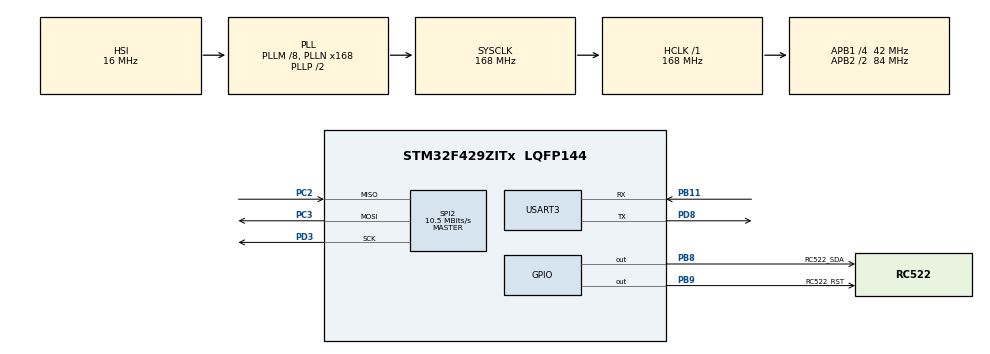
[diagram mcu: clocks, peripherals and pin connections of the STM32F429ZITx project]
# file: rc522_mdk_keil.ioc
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Mcu.Family=STM32F4
Mcu.Name=STM32F429ZITx
Mcu.Package=LQFP144
NVIC.PriorityGroup=NVIC_PRIORITYGROUP_4
NVIC.TIM1_UP_TIM10_IRQn=true\:15\:0\:false\:false\:true\:false\:true\:true
NVIC.TimeBase=TIM1_UP_TIM10_IRQn
NVIC.TimeBaseIP=TIM1
PA13.Mode=Serial_Wire
PA13.Signal=SYS_JTMS-SWDIO
PA14.Mode=Serial_Wire
PA14.Signal=SYS_JTCK-SWCLK
PB11.Mode=Asynchronous
PB11.Signal=USART3_RX
PB8.GPIO_Label=RC522_SDA
PB8.GPIO_Speed=GPIO_SPEED_FREQ_HIGH
PB8.Signal=GPIO_Output
PB9.GPIO_Label=RC522_RST
PB9.GPIO_Speed=GPIO_SPEED_FREQ_HIGH
PB9.Signal=GPIO_Output
PC2.Mode=Full_Duplex_Master
PC2.Signal=SPI2_MISO
PC3.Mode=Full_Duplex_Master
PC3.Signal=SPI2_MOSI
PD3.Mode=Full_Duplex_Master
PD3.Signal=SPI2_SCK
PD8.Mode=Asynchronous
PD8.Signal=USART3_TX
PH0/OSC_IN.Mode=HSE-External-Clock-Source
PH0/OSC_IN.Signal=RCC_OSC_IN
PH1/OSC_OUT.Mode=HSE-External-Clock-Source
PH1/OSC_OUT.Signal=RCC_OSC_OUT
ProjectManager.HeapSize=0x200
ProjectManager.StackSize=0x400
ProjectManager.TargetToolchain=MDK-ARM V5.32
RCC.48MHZClocksFreq_Value=48000000
RCC.AHBFreq_Value=168000000
RCC.APB1CLKDivider=RCC_HCLK_DIV4
RCC.APB1Freq_Value=42000000
RCC.APB1TimFreq_Value=84000000
RCC.APB2CLKDivider=RCC_HCLK_DIV2
RCC.APB2Freq_Value=84000000
RCC.APB2TimFreq_Value=168000000
RCC.CortexFreq_Value=168000000
RCC.HCLKFreq_Value=168000000
RCC.HSE_VALUE=8000000
RCC.HSI_VALUE=16000000
RCC.LSE_VALUE=32768
RCC.PLLM=8
RCC.PLLMUL=RCC_PLL_MUL9
RCC.PLLN=168
RCC.PLLQ=7
RCC.PRESCALERUSB=RCC_USBCLKSOURCE_PLL_DIV1_5
RCC.SYSCLKFreq_VALUE=168000000
RCC.SYSCLKSource=RCC_SYSCLKSOURCE_PLLCLK
RCC.SYSCLKSourceVirtual=RCC_SYSCLKSOURCE_PLLCLK
RCC.USBFreq_Value=48000000
RCC.VCOOutputFreq_Value=336000000
SPI2.BaudRatePrescaler=SPI_BAUDRATEPRESCALER_4
SPI2.CalculateBaudRate=10.5 MBits/s
SPI2.Direction=SPI_DIRECTION_2LINES
SPI2.Mode=SPI_MODE_MASTER
SPI2.VirtualType=VM_MASTER
USART3.VirtualMode=VM_ASYNC
VP_SYS_VS_tim1.Mode=TIM1
VP_TIM2_VS_ClockSourceINT.Mode=Internal
board=NUCLEO-F429ZI

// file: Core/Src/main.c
/* USER CODE BEGIN Header */
/**
  ******************************************************************************
  * @file           : main.c
  * @brief          : Main program body
  ******************************************************************************
  * @attention
  *
  * Copyright (c) 2023 STMicroelectronics.
  * All rights reserved.
  *
  * This software is licensed under terms that can be found in the LICENSE file
  * in the root directory of this software component.
  * If no LICENSE file comes with this software, it is provided AS-IS.
  *
  ******************************************************************************
  */
/* USER CODE END Header */
#include "main.h"
#include "spi.h"
#include "tim.h"
#include "usart.h"
#include "gpio.h"

/* USER CODE BEGIN Includes */
#include "rc522.h"
#include "stdio.h"
/* USER CODE END Includes */

void SystemClock_Config(void);

int main(void)
{

  /* MCU Configuration--------------------------------------------------------*/

  /* Reset of all peripherals, Initializes the Flash interface and the Systick. */
  HAL_Init();

  /* Configure the system clock */
  SystemClock_Config();

  /* Initialize all configured peripherals */
  MX_GPIO_Init();
  MX_SPI2_Init();
  MX_USART3_UART_Init();
  MX_TIM2_Init();
  /* USER CODE BEGIN 2 */
	printf("system start\r\n");
	RC522_Init();
	//printf("system start\n");
  /* USER CODE END 2 */

  /* Infinite loop */
  /* USER CODE BEGIN WHILE */
  uint8_t cardSerialNum[4] = {0x42, 0xBA, 0x47, 0x1E};
	uint8_t KEY_A[6] = {
		0xFF, 0xFF, 0xFF,
		0xFF, 0xFF, 0xFF};
	uint8_t data[] = {0x11, 0x66, 0x15, 0x44, 0x65, 0x22, 0x45, 0x88, 0x11, 0x66, 0x15, 0x44,0x65, 0x22, 0x45, 0x88};
	uint8_t addr = 0x08;
	writeCard(cardSerialNum, 0, KEY_A, 1, addr, data);
	//uint8_t data_1[] = {0x11, 0x66, 0x15, 0x44, 0x65, 0x22, 0x45, 0x88, 0x11, 0x66, 0x15, 0x44,0x65, 0x22, 0x45, 0x88};
	//writeCard(cardSerialNum, 0, KEY_A, 0, addr, data_1);
	//writeCard(cardSerialNum, 0, KEY_A, 1, addr, data);
	//status = writeBlock(addr, data);
	//printf("write status %d", status);
	while (1)
  {
    /* USER CODE END WHILE */

    /* USER CODE BEGIN 3 */
		//writeCard(cardSerialNum, 0, KEY_A, 0, 0x11, data);
		/*

		*/
//		if(getSerialNum(cardSerialNum) == MI_OK){
//			printf("find card:%x %x %x %x\r\n", cardSerialNum[0], cardSerialNum[1], cardSerialNum[2], cardSerialNum[3]);
//			HAL_Delay(1);
//			writeCard(cardSerialNum, 0, KEY_A, 1, 0x10, data);
//			/*
//			printf("read data from 0x10 block:");
//			for(int i=0;i<sizeof(data);i++){
//				printf("%x ", data[i]);
//			}
//			printf("\r\n");
//			*/
//		}else{
//			//printf("fail\n");
//		}
//		//writeCard(cardSerialNum, 0, KEY_A, 1, 0x10, data);
		HAL_Delay(1000);
  }
  /* USER CODE END 3 */
}

void SystemClock_Config(void)
{
  RCC_OscInitTypeDef RCC_OscInitStruct = {0};
  RCC_ClkInitTypeDef RCC_ClkInitStruct = {0};

  /** Configure the main internal regulator output voltage
  */
  __HAL_RCC_PWR_CLK_ENABLE();
  __HAL_PWR_VOLTAGESCALING_CONFIG(PWR_REGULATOR_VOLTAGE_SCALE1);

  /** Initializes the RCC Oscillators according to the specified parameters
  * in the RCC_OscInitTypeDef structure.
  */
  RCC_OscInitStruct.OscillatorType = RCC_OSCILLATORTYPE_HSI;
  RCC_OscInitStruct.HSIState = RCC_HSI_ON;
  RCC_OscInitStruct.HSICalibrationValue = RCC_HSICALIBRATION_DEFAULT;
  RCC_OscInitStruct.PLL.PLLState = RCC_PLL_ON;
  RCC_OscInitStruct.PLL.PLLSource = RCC_PLLSOURCE_HSI;
  RCC_OscInitStruct.PLL.PLLM = 8;
  RCC_OscInitStruct.PLL.PLLN = 168;
  RCC_OscInitStruct.PLL.PLLP = RCC_PLLP_DIV2;
  RCC_OscInitStruct.PLL.PLLQ = 7;
  if (HAL_RCC_OscConfig(&RCC_OscInitStruct) != HAL_OK)
  {
    Error_Handler();
  }

  /** Initializes the CPU, AHB and APB buses clocks
  */
  RCC_ClkInitStruct.ClockType = RCC_CLOCKTYPE_HCLK|RCC_CLOCKTYPE_SYSCLK
                              |RCC_CLOCKTYPE_PCLK1|RCC_CLOCKTYPE_PCLK2;
  RCC_ClkInitStruct.SYSCLKSource = RCC_SYSCLKSOURCE_PLLCLK;
  RCC_ClkInitStruct.AHBCLKDivider = RCC_SYSCLK_DIV1;
  RCC_ClkInitStruct.APB1CLKDivider = RCC_HCLK_DIV4;
  RCC_ClkInitStruct.APB2CLKDivider = RCC_HCLK_DIV2;

  if (HAL_RCC_ClockConfig(&RCC_ClkInitStruct, FLASH_LATENCY_5) != HAL_OK)
  {
    Error_Handler();
  }
}

void HAL_TIM_PeriodElapsedCallback(TIM_HandleTypeDef *htim)
{
  if (htim->Instance == TIM1) {
    HAL_IncTick();
  }
}

void Error_Handler(void)
{
  __disable_irq();
  while (1)
  {
  }
}
